# N32H7xx register map
Vendor: Nationstech Ltd.; File version: 1.0
CPU: CM7 r1p1, little endian, MPU, FPU, 4 interrupt priority bits
Registers are 32-bit, read-write, reset 0x0 unless marked. A register's access mark holds for its fields unless they carry their own. Offsets are from the block's base; [hi:lo] are bit positions; {n}, {i} and the like mark numbered series; 'fields as' and 'values as' point back to an identical list.

## FEMC — Flexible external memory controller
Base 0x5004C000
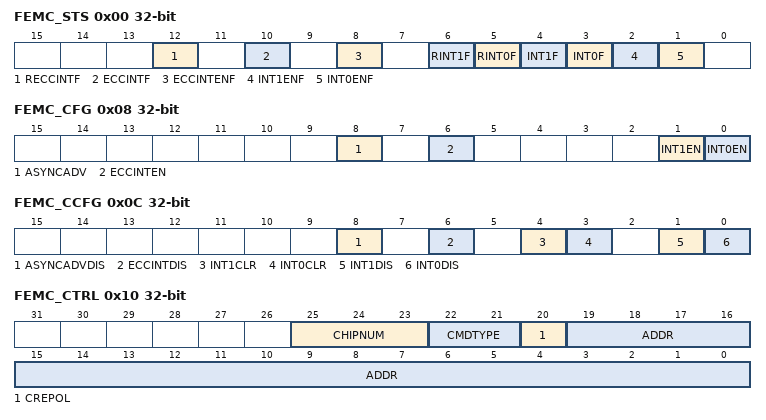
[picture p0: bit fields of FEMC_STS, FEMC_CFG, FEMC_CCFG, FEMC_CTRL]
0x00 FEMC_STS ro — Memory Controller Status Register
  [12] RECCINTF, [10] ECCINTF, [8] ECCINTENF, [6] RINT1F, [5] RINT0F, [4] INT1F, [3] INT0F, [2] INT1ENF, [1] INT0ENF
0x04 FEMC_STS1 ro reset 0x162D — Memory Interface Configuration Register
  [1:0] M0TYPE
0x08 FEMC_CFG wo — Set Configuration Register
  [8] ASYNCADV, [6] ECCINTEN, [1] INT1EN, [0] INT0EN
0x0C FEMC_CCFG wo — Clear Configuration Register
  [8] ASYNCADVDIS, [6] ECCINTDIS, [4] INT1CLR, [3] INT0CLR, [1] INT1DIS, [0] INT0DIS
0x10 FEMC_CTRL wo — Direct Command Register
  [25:23] CHIPNUM, [22:21] CMDTYPE, [20] CREPOL, [19:0] ADDR
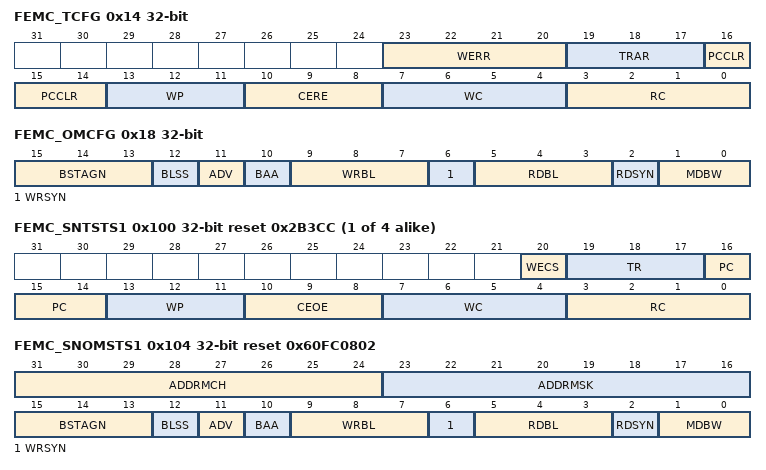
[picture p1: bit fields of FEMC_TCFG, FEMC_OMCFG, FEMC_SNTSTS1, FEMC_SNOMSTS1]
0x14 FEMC_TCFG wo — Set Cycles Register
  [23:20] WERR, [19:17] TRAR, [16:14] PCCLR, [13:11] WP, [10:8] CERE, [7:4] WC, [3:0] RC
0x18 FEMC_OMCFG wo — Set Operating Mode Register
  [15:13] BSTAGN
  [12] BLSS
  [11] ADV
  [10] BAA
  [9:7] WRBL
  [6] WRSYN
  [5:3] RDBL
  [2] RDSYN — RDSYNC
  [1:0] MDBW
0x20 FEMC_RPE — Refresh Period 0 Register
  [3:0] REFPRD
{0xE0+0x20*i} FEMC_SNTSTS{i} ro reset 0x2B3CC (i=1..4) — SRAM chip {i} Cycles Register
  [20] WECS, [19:17] TR, [16:14] PC, [13:11] WP, [10:8] CEOE, [7:4] WC, [3:0] RC
0x104 FEMC_SNOMSTS1 ro reset 0x60FC0802 — SRAM chip 1 Operating Mode Status Register
  [31:24] ADDRMCH, [23:16] ADDRMSK, [15:13] BSTAGN, [12] BLSS, [11] ADV, [10] BAA, [9:7] WRBL, [6] WRSYN, [5:3] RDBL, [2] RDSYN, [1:0] MDBW
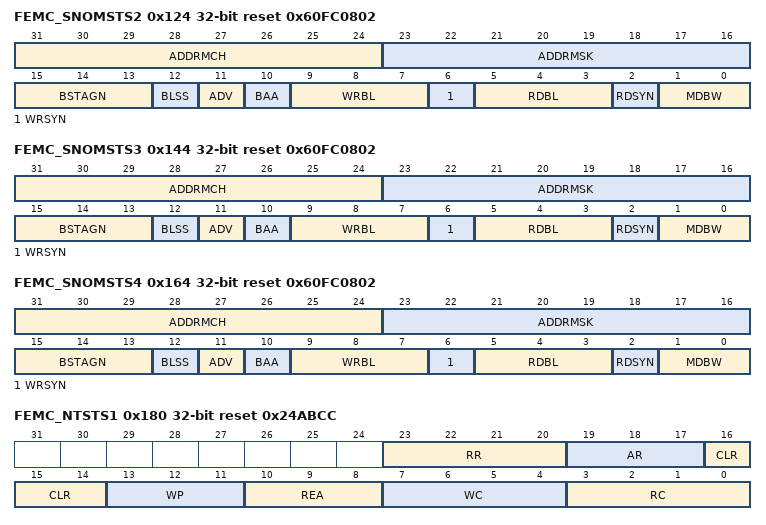
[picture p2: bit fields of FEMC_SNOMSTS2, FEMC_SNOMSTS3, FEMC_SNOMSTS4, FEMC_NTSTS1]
0x124 FEMC_SNOMSTS2 ro reset 0x60FC0802 — SRAM chip 3 Operating Mode Status Register
  fields as FEMC_SNOMSTS1
0x144 FEMC_SNOMSTS3 ro reset 0x60FC0802 — SRAM chip 3 Operating Mode Status Register
  fields as FEMC_SNOMSTS1
0x164 FEMC_SNOMSTS4 ro reset 0x60FC0802 — SRAM chip 4 Operating Mode Status Register
  fields as FEMC_SNOMSTS1
0x180 FEMC_NTSTS1 ro reset 0x24ABCC — NAND chip 1 Cycles Register
  [23:20] RR, [19:17] AR, [16:14] CLR, [13:11] WP, [10:8] REA, [7:4] WC, [3:0] RC
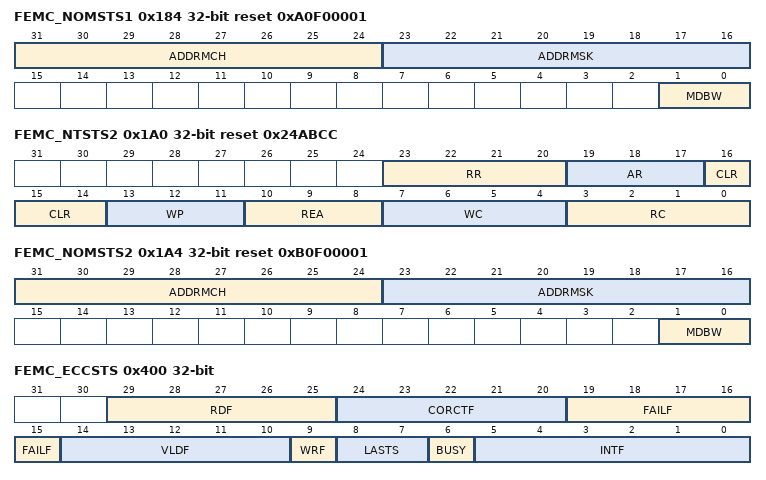
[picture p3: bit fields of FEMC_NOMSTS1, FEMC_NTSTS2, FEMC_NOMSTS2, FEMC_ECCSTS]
0x184 FEMC_NOMSTS1 ro reset 0xA0F00001 — NAND chip 1 Operating Mode Status Register
  [31:24] ADDRMCH, [23:16] ADDRMSK, [1:0] MDBW
0x1A0 FEMC_NTSTS2 ro reset 0x24ABCC — NAND chip 2 Cycles Register
  fields as FEMC_NTSTS1
0x1A4 FEMC_NOMSTS2 ro reset 0xB0F00001 — NAND chip 2 Operating Mode Status Register
  [31:24] ADDRMCH, [23:16] ADDRMSK, [1:0] MDBW
0x400 FEMC_ECCSTS — NAND ECC Status Register
  [29:25] RDF ro, [24:20] CORCTF ro, [19:15] FAILF ro, [14:10] VLDF ro, [9] WRF ro, [8:7] LASTS ro, [6] BUSY ro, [5:0] INTF
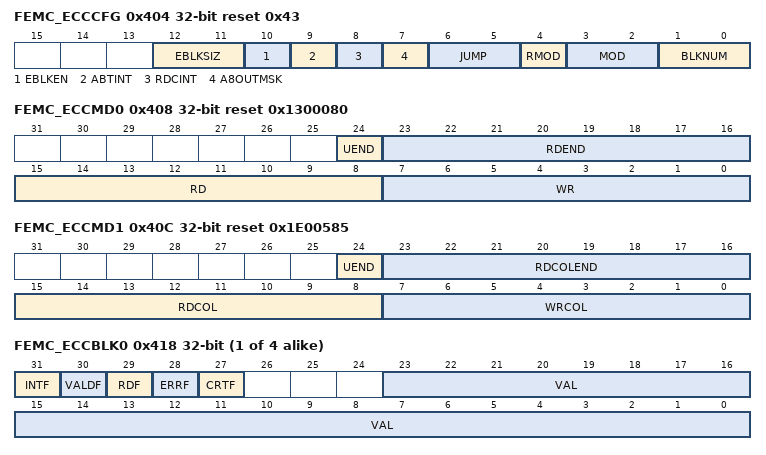
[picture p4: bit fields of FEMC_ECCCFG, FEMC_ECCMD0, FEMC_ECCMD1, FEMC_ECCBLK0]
0x404 FEMC_ECCCFG reset 0x43 — NAND ECC Configuration Register
  [12:11] EBLKSIZ, [10] EBLKEN, [9] ABTINT, [8] RDCINT, [7] A8OUTMSK, [6:5] JUMP, [4] RMOD, [3:2] MOD, [1:0] BLKNUM
0x408 FEMC_ECCMD0 reset 0x1300080 — NAND ECC Command 0 Register
  [24] UEND, [23:16] RDEND, [15:8] RD, [7:0] WR
0x40C FEMC_ECCMD1 reset 0x1E00585 — NAND ECC Command 1 Register
  [24] UEND, [23:16] RDCOLEND, [15:8] RDCOL, [7:0] WRCOL
0x410 FEMC_ECCADDR0 wo — NAND ECC Address 0 Register
  [31:0] ADDR
0x414 FEMC_ECCADDR1 wo — NAND ECC Address 1 Register
  [23:0] ADDR
{0x418+4i} FEMC_ECCBLK{i} (i=0..3) — NAND ECC Block {i} Registers
  [31] INTF, [30] VALDF, [29] RDF, [28] ERRF, [27] CRTF, [23:0] VAL
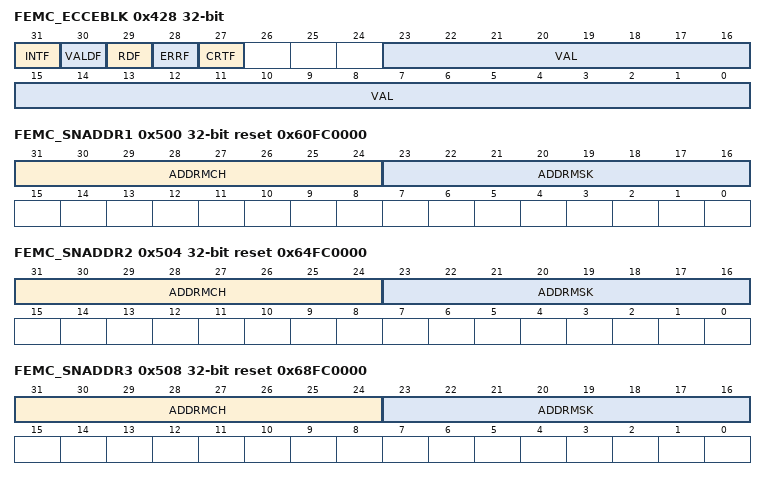
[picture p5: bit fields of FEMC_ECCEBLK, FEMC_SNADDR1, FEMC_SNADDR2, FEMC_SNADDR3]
0x428 FEMC_ECCEBLK — NAND ECC Extra Block Register
  [31] INTF, [30] VALDF, [29] RDF, [28] ERRF, [27] CRTF, [23:0] VAL
0x500 FEMC_SNADDR1 reset 0x60FC0000 — Set address 0_1 register
  [31:24] ADDRMCH, [23:16] ADDRMSK
0x504 FEMC_SNADDR2 reset 0x64FC0000 — Set address 0_2 register
  [31:24] ADDRMCH, [23:16] ADDRMSK
0x508 FEMC_SNADDR3 reset 0x68FC0000 — Set address 0_3 register
  [31:24] ADDRMCH, [23:16] ADDRMSK
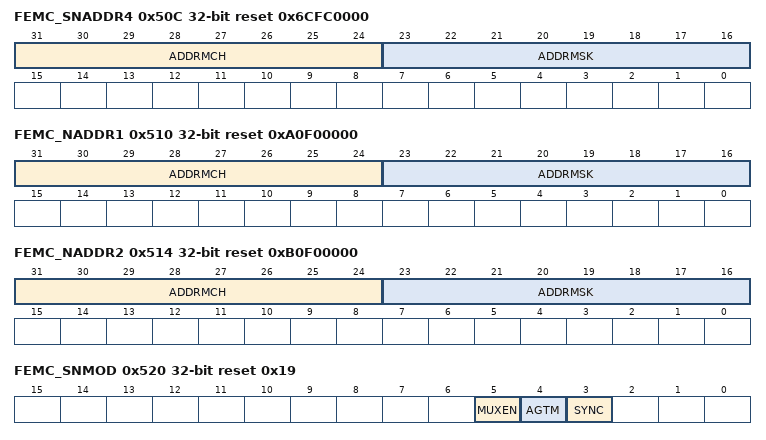
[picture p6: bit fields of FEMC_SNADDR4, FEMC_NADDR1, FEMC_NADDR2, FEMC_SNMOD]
0x50C FEMC_SNADDR4 reset 0x6CFC0000 — Set address 0_4 register
  [31:24] ADDRMCH, [23:16] ADDRMSK
0x510 FEMC_NADDR1 reset 0xA0F00000 — Set address 1_1 register
  [31:24] ADDRMCH, [23:16] ADDRMSK
0x514 FEMC_NADDR2 reset 0xB0F00000 — Set address 1_2 register
  [31:24] ADDRMCH, [23:16] ADDRMSK
0x520 FEMC_SNMOD reset 0x19 — SRAM miscellaneous mode register
  [5] MUXEN, [4] AGTM, [3] SYNC
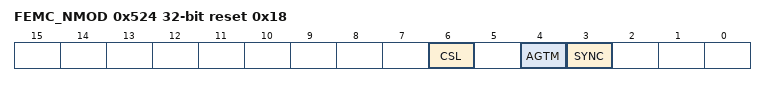
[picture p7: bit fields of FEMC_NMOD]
0x524 FEMC_NMOD reset 0x18 — NAND miscellaneous mode register
  [6] CSL, [4] AGTM, [3] SYNC
0x528 FEMC_REMAP — NAND REMAP
  [0] REMAP
